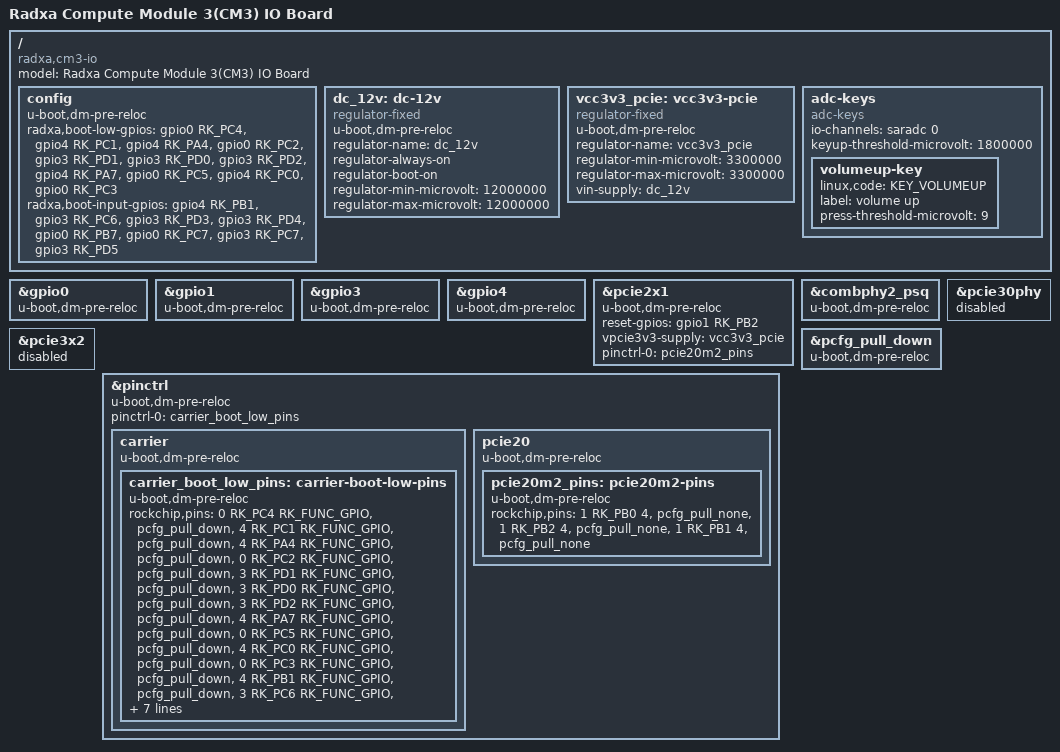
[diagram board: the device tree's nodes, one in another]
// SPDX-License-Identifier: (GPL-2.0+ OR MIT)
/*
 * Copyright (c) 2020 Rockchip Electronics Co., Ltd.
 * Copyright (c) 2021 Radxa Limited.
 *
 */

/dts-v1/;

#include "rk3566-radxa-cm3.dtsi"

/delete-node/ &user_led;

/ {
	model = "Radxa Compute Module 3(CM3) IO Board";
	compatible = "radxa,cm3-io", "radxa,cm3", "rockchip,rk3566";

	config {
		u-boot,dm-pre-reloc;
		u-boot,dm-spl;
		/*
		 * GPIO0_B2/SYS_LED1 and GPIO0_A2/SYS_LED2 are PMIC signals.
		 */
		radxa,boot-low-gpios =
			<&gpio0 RK_PC4 GPIO_ACTIVE_HIGH>, /* POWER_EN */
			<&gpio4 RK_PC1 GPIO_ACTIVE_HIGH>, /* SYS_LED3 */
			<&gpio4 RK_PA4 GPIO_ACTIVE_HIGH>, /* GPIO_O1 */
			<&gpio0 RK_PC2 GPIO_ACTIVE_HIGH>, /* GPIO_O2 */
			<&gpio3 RK_PD1 GPIO_ACTIVE_HIGH>, /* GPIO_O3 */
			<&gpio3 RK_PD0 GPIO_ACTIVE_HIGH>, /* GPIO_O4 */
			<&gpio3 RK_PD2 GPIO_ACTIVE_HIGH>, /* GPIO_O5 */
			<&gpio4 RK_PA7 GPIO_ACTIVE_HIGH>, /* GPIO_O6 */
			<&gpio0 RK_PC5 GPIO_ACTIVE_HIGH>, /* GPIO_O7 */
			<&gpio4 RK_PC0 GPIO_ACTIVE_HIGH>, /* GPIO_O8 */
			<&gpio0 RK_PC3 GPIO_ACTIVE_HIGH>; /* GPIO_BUZZER */
		radxa,boot-input-gpios =
			<&gpio4 RK_PB1 GPIO_ACTIVE_HIGH>, /* GPIO_IN1 */
			<&gpio3 RK_PC6 GPIO_ACTIVE_HIGH>, /* GPIO_IN2 */
			<&gpio3 RK_PD3 GPIO_ACTIVE_HIGH>, /* GPIO_IN3 */
			<&gpio3 RK_PD4 GPIO_ACTIVE_HIGH>, /* GPIO_IN4 */
			<&gpio0 RK_PB7 GPIO_ACTIVE_HIGH>, /* GPIO_IN5 */
			<&gpio0 RK_PC7 GPIO_ACTIVE_HIGH>, /* GPIO_IN6 */
			<&gpio3 RK_PC7 GPIO_ACTIVE_HIGH>, /* GPIO_IN7 */
			<&gpio3 RK_PD5 GPIO_ACTIVE_HIGH>; /* GPIO_IN8 */
	};

	dc_12v: dc-12v {
		u-boot,dm-pre-reloc;
		compatible = "regulator-fixed";
		regulator-name = "dc_12v";
		regulator-always-on;
		regulator-boot-on;
		regulator-min-microvolt = <12000000>;
		regulator-max-microvolt = <12000000>;
	};

	vcc3v3_pcie: vcc3v3-pcie {
		u-boot,dm-pre-reloc;
		compatible = "regulator-fixed";
		regulator-name = "vcc3v3_pcie";
		regulator-min-microvolt = <3300000>;
		regulator-max-microvolt = <3300000>;
		vin-supply = <&dc_12v>;
	};

	adc-keys {
		compatible = "adc-keys";
		io-channels = <&saradc 0>;
		io-channel-names = "buttons";
		keyup-threshold-microvolt = <1800000>;
		u-boot,dm-spl;
		status = "okay";

		volumeup-key {
			u-boot,dm-spl;
			linux,code = <KEY_VOLUMEUP>;
			label = "volume up";
			press-threshold-microvolt = <9>;
		};
	};
};

&gpio0 {
	u-boot,dm-pre-reloc;
	u-boot,dm-spl;
	status = "okay";
};

&gpio1 {
	u-boot,dm-pre-reloc;
	status = "okay";
};

&gpio3 {
	u-boot,dm-pre-reloc;
	u-boot,dm-spl;
	status = "okay";
};

&gpio4 {
	u-boot,dm-pre-reloc;
	u-boot,dm-spl;
	status = "okay";
};

&pcie2x1 {
	u-boot,dm-pre-reloc;
	status = "okay";
	reset-gpios = <&gpio1 RK_PB2 GPIO_ACTIVE_HIGH>;
	vpcie3v3-supply = <&vcc3v3_pcie>;
	pinctrl-0 = <&pcie20m2_pins>;
};

&combphy2_psq {
	u-boot,dm-pre-reloc;
	status = "okay";
};

&pcie30phy {
	status = "disabled";
};

&pcie3x2 {
	status = "disabled";
};

&pinctrl {
	u-boot,dm-pre-reloc;
	u-boot,dm-spl;
	pinctrl-names = "default";
	pinctrl-0 = <&carrier_boot_low_pins>;

	carrier {
		u-boot,dm-pre-reloc;
		u-boot,dm-spl;

		carrier_boot_low_pins: carrier-boot-low-pins {
			u-boot,dm-pre-reloc;
			u-boot,dm-spl;
			/* Directions are set by the early board hook. */
			rockchip,pins =
				<0 RK_PC4 RK_FUNC_GPIO &pcfg_pull_down>,
				<4 RK_PC1 RK_FUNC_GPIO &pcfg_pull_down>,
				<4 RK_PA4 RK_FUNC_GPIO &pcfg_pull_down>,
				<0 RK_PC2 RK_FUNC_GPIO &pcfg_pull_down>,
				<3 RK_PD1 RK_FUNC_GPIO &pcfg_pull_down>,
				<3 RK_PD0 RK_FUNC_GPIO &pcfg_pull_down>,
				<3 RK_PD2 RK_FUNC_GPIO &pcfg_pull_down>,
				<4 RK_PA7 RK_FUNC_GPIO &pcfg_pull_down>,
				<0 RK_PC5 RK_FUNC_GPIO &pcfg_pull_down>,
				<4 RK_PC0 RK_FUNC_GPIO &pcfg_pull_down>,
				<0 RK_PC3 RK_FUNC_GPIO &pcfg_pull_down>,
				<4 RK_PB1 RK_FUNC_GPIO &pcfg_pull_down>,
				<3 RK_PC6 RK_FUNC_GPIO &pcfg_pull_down>,
				<3 RK_PD3 RK_FUNC_GPIO &pcfg_pull_down>,
				<3 RK_PD4 RK_FUNC_GPIO &pcfg_pull_down>,
				<0 RK_PB7 RK_FUNC_GPIO &pcfg_pull_down>,
				<0 RK_PC7 RK_FUNC_GPIO &pcfg_pull_down>,
				<3 RK_PC7 RK_FUNC_GPIO &pcfg_pull_down>,
				<3 RK_PD5 RK_FUNC_GPIO &pcfg_pull_down>;
		};
	};

	pcie20 {
		u-boot,dm-pre-reloc;

		pcie20m2_pins: pcie20m2-pins {
			u-boot,dm-pre-reloc;
			rockchip,pins =
				/* pcie20_clkreqnm2 */
				<1 RK_PB0 4 &pcfg_pull_none>,
				/* pcie20_perstnm2 */
				<1 RK_PB2 4 &pcfg_pull_none>,
				/* pcie20_wakenm2 */
				<1 RK_PB1 4 &pcfg_pull_none>;
		};
	};
};

&pcfg_pull_down {
	u-boot,dm-pre-reloc;
	u-boot,dm-spl;
};
